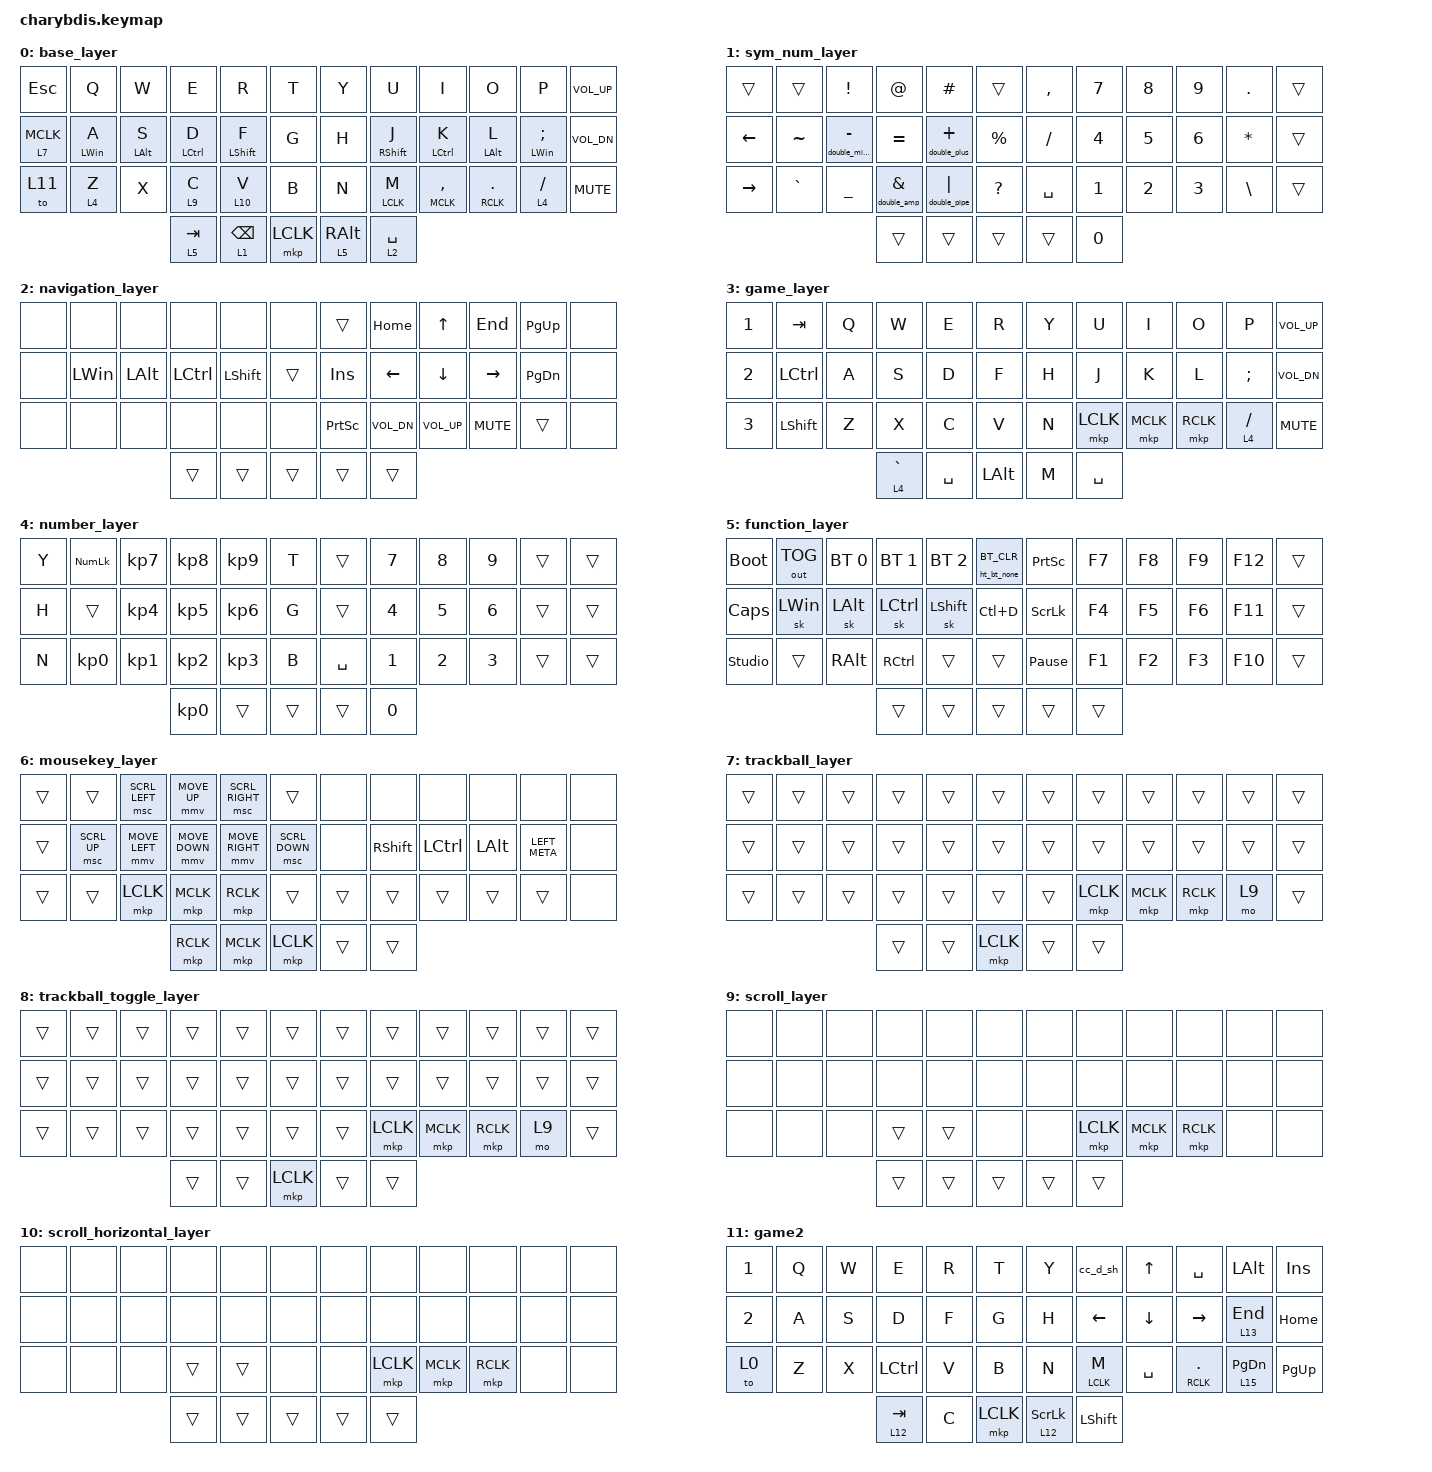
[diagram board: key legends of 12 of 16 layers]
#include <behaviors/mouse_keys.dtsi>
#include <dt-bindings/zmk/mouse.h>
#include <behaviors.dtsi>
#include <dt-bindings/zmk/bt.h>
#include <dt-bindings/zmk/keys.h>
#include <dt-bindings/zmk/outputs.h>
#include <dt-bindings/zmk/pointing.h>

//#include <dt-bindings/zmk/pointing.h>
// / {
//     chosen { zmk,matrix_transform = &default_transform; };
// };

#define LBASE 0
#define LSYM 1
#define LNAV 2
#define LGAME 3
#define LNUM 4
#define LFUNC 5
#define LMSE 6
#define LTRAC 7
#define LTOG 8
#define LSCR 9
#define LSCRH 10
#define LGAME2 11
#define LGAME_LEFT 13
#define LGAME_LEFT2 14
#define LGAME2NUM 15

&lt { quick-tap-ms = <220>; };

/ {
    trackball_auto_listener {
        compatible = "zmk,input-behavior-listener";
        device = <&vtrackball>;
        layers = <LBASE LTOG>;
        evt-type = <INPUT_EV_REL>;
        x-input-code = <INPUT_REL_X>;
        y-input-code = <INPUT_REL_Y>;
        scale-multiplier = <1>;
        scale-divisor = <3>;
        bindings = <&ib_toggle_layer LTRAC>;
    };

    trackball_listener {
        compatible = "zmk,input-behavior-listener";
        device = <&vtrackball>;
        layers = <LGAME LMSE LTRAC LGAME2 LGAME_LEFT LGAME_LEFT2>;
        evt-type = <INPUT_EV_REL>;
        x-input-code = <INPUT_REL_X>;
        y-input-code = <INPUT_REL_Y>;
        scale-multiplier = <1>;
        scale-divisor = <3>;
    };

    // input config for snipe mode

    trackball_snipe_listener {
        compatible = "zmk,input-behavior-listener";
        device = <&vtrackball>;
        layers = <LSYM>;
        evt-type = <INPUT_EV_REL>;
        x-input-code = <INPUT_REL_X>;
        y-input-code = <INPUT_REL_Y>;
        scale-multiplier = <1>;
        scale-divisor = <7>;
    };

    // input config for mouse scroll mode

    trackball_scroll_listener {
        compatible = "zmk,input-behavior-listener";
        device = <&vtrackball>;
        layers = <LSCR LNUM LGAME2NUM>;
        evt-type = <INPUT_EV_REL>;
        x-input-code = <INPUT_REL_MISC>;
        y-input-code = <INPUT_REL_WHEEL>;
        y-invert;
        bindings = <&ib_wheel_scaler 1 32>;
    };

    // input config for mouse scroll mode (horizontal)

    trackball_h_scroll_listener {
        compatible = "zmk,input-behavior-listener";
        device = <&vtrackball>;
        layers = <LSCRH>;
        evt-type = <INPUT_EV_REL>;
        x-input-code = <INPUT_REL_HWHEEL>;
        y-input-code = <INPUT_REL_MISC>;
        bindings = <&ib_h_wheel_scaler 1 32>;
    };

    // define a resolution down scaler only for INPUT_REL_WHEEL

    ib_wheel_scaler: ib_wheel_scaler {
        compatible = "zmk,input-behavior-scaler";
        #binding-cells = <2>;
        evt-type = <INPUT_EV_REL>;
        input-code = <INPUT_REL_WHEEL>;
    };

    // define a resolution down scaler only for INPUT_REL_HWHEEL (horizontal)

    ib_h_wheel_scaler: ib_h_wheel_scaler {
        compatible = "zmk,input-behavior-scaler";
        #binding-cells = <2>;
        evt-type = <INPUT_EV_REL>;
        input-code = <INPUT_REL_HWHEEL>;
    };

    // adjust cooldown waiting period for mouse key layer after activated

    ib_toggle_layer: ib_toggle_layer {
        compatible = "zmk,input-behavior-tog-layer";
        #binding-cells = <1>;
        time-to-live-ms = <800>;
    };

    behaviors {
        ht_mo_to: ht_moL_toL {
            compatible = "zmk,behavior-hold-tap";
            bindings = <&mo>, <&to>;

            #binding-cells = <2>;
            flavor = "balanced";
            tapping-term-ms = <200>;
        };

        ht_hm_rshft: hm_Rshift {
            compatible = "zmk,behavior-hold-tap";
            label = "ht_hm_rshft";
            bindings = <&kp>, <&kp>;

            #binding-cells = <2>;
            flavor = "tap-preferred";
            tapping-term-ms = <160>;
            quick-tap-ms = <220>;
        };

        ht_hm_lshft: hm_Lshift {
            compatible = "zmk,behavior-hold-tap";
            label = "ht_hm_lshft";
            bindings = <&kp>, <&kp>;

            #binding-cells = <2>;
            flavor = "tap-preferred";
            tapping-term-ms = <160>;
            quick-tap-ms = <220>;
        };

        ht_hm: homerow_mod {
            compatible = "zmk,behavior-hold-tap";
            label = "Homerow Mod";
            bindings = <&kp>, <&kp>;

            #binding-cells = <2>;
            tapping-term-ms = <220>;
            flavor = "tap-preferred";
            quick-tap-ms = <220>;
        };

        ht_gte_gt: gt_hold_gte {
            compatible = "zmk,behavior-hold-tap";
            label = "GT_GTE";
            bindings = <&gte>, <&kp>;

            #binding-cells = <2>;
            tapping-term-ms = <200>;
            flavor = "tap-preferred";
            quick-tap-ms = <200>;
        };

        ht_lte_lt: lt_hold_lte {
            compatible = "zmk,behavior-hold-tap";
            label = "LT_LTE";
            bindings = <&lte>, <&kp>;

            #binding-cells = <2>;
            tapping-term-ms = <200>;
            flavor = "tap-preferred";
            quick-tap-ms = <200>;
        };

        ht_lpar_lr: lpar_hold_lr {
            compatible = "zmk,behavior-hold-tap";
            label = "LPAR_LR";
            bindings = <&parenthesis_lr>, <&kp>;

            #binding-cells = <2>;
            tapping-term-ms = <200>;
            flavor = "tap-preferred";
            quick-tap-ms = <200>;
        };

        ht_lbrace_lr: lbrace_hold_lr {
            compatible = "zmk,behavior-hold-tap";
            label = "LBRACE_LR";
            bindings = <&braces_lr>, <&kp>;

            #binding-cells = <2>;
            tapping-term-ms = <200>;
            flavor = "tap-preferred";
            quick-tap-ms = <200>;
        };

        ht_lbracket_lr: lbracket_hold_lr {
            compatible = "zmk,behavior-hold-tap";
            label = "LBRACKET_LR";
            bindings = <&brackets_lr>, <&kp>;

            #binding-cells = <2>;
            tapping-term-ms = <200>;
            flavor = "tap-preferred";
            quick-tap-ms = <200>;
        };

        lt_mo_mkp: lt_moL_mouseKP {
            compatible = "zmk,behavior-hold-tap";
            label = "LT_MOUSEKP";
            bindings = <&mo>, <&mkp>;

            #binding-cells = <2>;
            tapping-term-ms = <200>;
        };

        ht_mkp_kp: ht_mouseKP_KP {
            compatible = "zmk,behavior-hold-tap";
            label = "HT_MOUSEKP";
            bindings = <&mkp>, <&kp>;

            #binding-cells = <2>;
            tapping-term-ms = <220>;
            quick-tap-ms = <150>;
            flavor = "tap-preferred";
        };

        mm_test: mm_test {
            compatible = "zmk,behavior-mod-morph";
            label = "MM_TEST";
            bindings = <&kp A>, <&kp B>;

            #binding-cells = <0>;
            mods = <(MOD_LSFT|MOD_RSFT)>;
            keep-mods = <(MOD_RSFT)>;
        };

        ht_pipe_double: ht_pipe_double {
            compatible = "zmk,behavior-hold-tap";
            label = "HT_PIPE_DOUBLE";
            bindings = <&double_pipe>, <&kp>;

            #binding-cells = <2>;
            tapping-term-ms = <200>;
            flavor = "tap-preferred";
            quick-tap-ms = <200>;
        };

        ht_amp_double: ht_amp_double {
            compatible = "zmk,behavior-hold-tap";
            label = "HT_AMP_DOUBLE";
            bindings = <&double_amp>, <&kp>;

            #binding-cells = <2>;
            tapping-term-ms = <200>;
            flavor = "tap-preferred";
            quick-tap-ms = <200>;
        };

        ht_bt_none: ht_bt_none {
            compatible = "zmk,behavior-hold-tap";
            label = "HT_BT_NONE";
            bindings = <&bt>, <&none>;

            #binding-cells = <2>;
            tapping-term-ms = <220>;
        };

        ht_mo_tog: ht_mo_tog {
            compatible = "zmk,behavior-hold-tap";
            label = "HT_MO_TOG";
            bindings = <&mo>, <&tog>;

            #binding-cells = <2>;
            tapping-term-ms = <200>;
        };

        ht_plus_double: ht_plus_double {
            compatible = "zmk,behavior-hold-tap";
            label = "HT_PLUS_DOUBLE";
            bindings = <&double_plus>, <&kp>;

            #binding-cells = <2>;
            tapping-term-ms = <200>;
            flavor = "tap-preferred";
            quick-tap-ms = <200>;
        };

        ht_minus_double: ht_minus_double {
            compatible = "zmk,behavior-hold-tap";
            label = "HT_MINUS_DOUBLE";
            bindings = <&double_minus>, <&kp>;

            #binding-cells = <2>;
            tapping-term-ms = <200>;
            flavor = "tap-preferred";
            quick-tap-ms = <200>;
        };

        td_f_7_8_9: td_f_7_8_9 {
            compatible = "zmk,behavior-tap-dance";
            label = "TD_F_7_8_9";
            #binding-cells = <0>;
            bindings = <&kp F>, <&kp N7>, <&kp N8>, <&kp N9>;
        };
    };

    combos {
        compatible = "zmk,combos";

        combo_lpar {
            timeout-ms = <46>;
            key-positions = <16 15>;
            bindings = <&ht_lpar_lr 0 LEFT_PARENTHESIS>;
            layers = <0 1 7 8 2>;
        };

        combo_rpar {
            timeout-ms = <45>;
            key-positions = <19 20>;
            bindings = <&kp RPAR>;
            layers = <0 7 1 8>;
        };

        combo_lbkt {
            timeout-ms = <45>;
            key-positions = <14 16>;
            bindings = <&ht_lbracket_lr 0 LEFT_BRACKET>;
            layers = <0 1 7 8>;
        };

        combo_rbkt {
            timeout-ms = <45>;
            key-positions = <19 21>;
            bindings = <&kp RBKT>;
            layers = <0 7 8 1>;
        };

        combo_lbrc {
            timeout-ms = <45>;
            key-positions = <14 15>;
            bindings = <&ht_lbrace_lr 0 LEFT_BRACE>;
            layers = <0 1 7 8>;
        };

        combo_rbrc {
            timeout-ms = <45>;
            key-positions = <20 21>;
            bindings = <&kp RIGHT_BRACE>;
            layers = <0 7 1 8>;
        };

        combo_lt {
            bindings = <&ht_lte_lt 0 LT>;
            key-positions = <14 3>;
            timeout-ms = <46>;
            layers = <0 1 7 8>;
        };

        combo_gt {
            bindings = <&ht_gte_gt 0 GT>;
            key-positions = <21 8>;
            timeout-ms = <45>;
            layers = <0 7 8 1>;
        };

        combo_copy {
            bindings = <&kp LC(C)>;
            key-positions = <27 15>;
            layers = <0 7 8>;
        };

        combo_paste {
            bindings = <&kp LC(V)>;
            key-positions = <16 28>;
            layers = <0 7 8>;
        };

        combo_num0 {
            bindings = <&kp N0>;
            key-positions = <31 19>;
            layers = <0 1 4 7 8>;
        };

        combo_num1 {
            bindings = <&kp NUMBER_1>;
            key-positions = <32 20>;
            layers = <0 1 4 7 8>;
        };

        combo_altF4 {
            bindings = <&kp LA(F4)>;
            key-positions = <1 4>;
            layers = <0 7 8>;
        };

        combo_escL {
            bindings = <&kp ESCAPE>;
            key-positions = <28 27>;
            layers = <0 1 2 6 7 8 13 14>;
        };

        combo_delL {
            bindings = <&kp DEL>;
            key-positions = <26 28>;
            layers = <0 1 7 8 2 4>;
        };

        combo_enterL {
            bindings = <&kp ENTER>;
            key-positions = <27 26>;
            layers = <0 7 1 8 13 14>;
        };

        combo_sqtL {
            bindings = <&kp SQT>;
            key-positions = <3 16>;
            layers = <0 1 7 8 2>;
        };

        combo_toggle_Trackball {
            bindings = <&tog 8>;
            key-positions = <31 34>;
            layers = <0 7 8>;
        };

        combo_toggle_game {
            bindings = <&tog 11>;
            key-positions = <24 35>;
            layers = <0 3 11>;
        };

        combo_space {
            bindings = <&kp SPACE>;
            key-positions = <16 4>;
            layers = <0 7 1 8 11 13 14>;
        };

        combo_caps {
            bindings = <&caps_word>;
            key-positions = <2 14>;
            layers = <0 7 1 8>;
        };

        combo_bspc {
            bindings = <&kp BACKSPACE>;
            key-positions = <7 19>;
            layers = <0 1 6 8 11 13 14>;
        };

        combo_tab {
            bindings = <&kp TAB>;
            key-positions = <8 20>;
            layers = <0 1 7 8>;
        };

        combo_forward {
            bindings = <&kp LA(RIGHT)>;
            key-positions = <30 31>;
            layers = <0 7 8 6>;
        };

        combo_back {
            bindings = <&kp LA(LEFT_ARROW)>;
            key-positions = <18 19>;
            layers = <0 7 8 6>;
        };

        combo_kor_T {
            bindings = <&kp LG(GRAVE)>;
            key-positions = <3 4>;
            timeout-ms = <50>;
            layers = <0 7 8>;
        };

        combo_kor_R {
            bindings = <&kp LC(LG(GRAVE))>;
            key-positions = <3 2>;
            timeout-ms = <50>;
            layers = <0 7 8>;
        };

        combo_escR {
            bindings = <&kp ESCAPE>;
            key-positions = <32 31>;
            layers = <0 1 7 8 2 3 11 13 14>;
        };

        combo_delR {
            bindings = <&kp DELETE>;
            key-positions = <31 33>;
            layers = <0 1 6 8 3 11 13 14>;
        };

        combo_enterR {
            bindings = <&kp ENTER>;
            key-positions = <33 32>;
            layers = <0 1 7 8 3 11 13 14>;
        };

        combo_sqtR {
            bindings = <&kp DQT>;
            key-positions = <8 19>;
            layers = <0 1 7 8>;
        };

        combo_caret {
            bindings = <&kp CARET>;
            key-positions = <15 28>;
            layers = <0 1 7 8>;
        };

        combo_dollar {
            bindings = <&kp DOLLAR>;
            key-positions = <31 20>;
            layers = <0 1 7 8>;
        };

        combo_scroll {
            bindings = <&tog 9>;
            key-positions = <40 39>;
            layers = <0 6 8 9>;
        };

        game_left_3 {
            bindings = <&kp NUMBER_3>;
            key-positions = <2 3>;
            layers = <13 14>;
        };

        game_left_4 {
            bindings = <&kp NUMBER_4>;
            key-positions = <3 4>;
            layers = <13 14>;
        };

        toggle_game_left {
            bindings = <&tog 13>;
            key-positions = <28 29>;
            layers = <11 13>;
        };

        game_shift {
            bindings = <&kp LEFT_SHIFT>;
            key-positions = <26 25>;
            layers = <13 14>;
        };

        toggle_14 {
            bindings = <&tog 14>;
            key-positions = <28 16>;
            layers = <11 14>;
        };

        toggle_game_left_r {
            bindings = <&tog 13>;
            key-positions = <30 31>;
            layers = <11 13>;
        };

        toggle_game_left2_r {
            bindings = <&tog 14>;
            key-positions = <19 31>;
            layers = <11 14>;
        };
    };

    macros {
        gte: gte {
            compatible = "zmk,behavior-macro";
            #binding-cells = <0>;
            bindings = <&macro_tap_time 5>, <&kp GT &kp EQUAL>;

            label = "GTE";
        };

        lte: lte {
            compatible = "zmk,behavior-macro";
            #binding-cells = <0>;
            bindings = <&macro_tap_time 5>, <&kp LT &kp EQUAL>;

            label = "LTE";
        };

        parenthesis_lr: parenthesis_lr {
            compatible = "zmk,behavior-macro";
            #binding-cells = <0>;
            bindings = <&macro_tap_time 5>, <&kp LPAR &kp RPAR>;

            label = "PARENTHESIS_LR";
        };

        braces_lr: braces_lr {
            compatible = "zmk,behavior-macro";
            #binding-cells = <0>;
            bindings = <&macro_tap_time 5>, <&kp LBRC &kp RBRC>;

            label = "BRACES_LR";
        };

        brackets_lr: brackets_lr {
            compatible = "zmk,behavior-macro";
            #binding-cells = <0>;
            bindings = <&macro_tap_time 5>, <&kp LBKT &kp RBKT>;

            label = "BRACKETS_LR";
        };

        double_pipe: double_pipe {
            compatible = "zmk,behavior-macro";
            #binding-cells = <0>;
            bindings = <&macro_tap_time 5>, <&kp PIPE &kp PIPE>;

            label = "DOUBLE_PIPE";
        };

        double_amp: double_amp {
            compatible = "zmk,behavior-macro";
            #binding-cells = <0>;
            bindings = <&macro_tap_time 5>, <&kp AMPS &kp AMPS>;

            label = "DOUBLE_AMP";
        };

        double_plus: hold_plus {
            compatible = "zmk,behavior-macro";
            #binding-cells = <0>;
            bindings = <&macro_tap_time 5>, <&kp PLUS &kp PLUS>;

            label = "HOLD_PLUS";
        };

        double_minus: double_minus {
            compatible = "zmk,behavior-macro";
            #binding-cells = <0>;
            bindings = <&macro_tap_time 5>, <&kp MINUS &kp MINUS>;

            label = "DOUBLE_MINUS";
        };

        d_sh: crumeso {
            compatible = "zmk,behavior-macro";
            #binding-cells = <0>;
            bindings =
                <&kp D>,
                <&macro_wait_time 200>,
                <&kp LEFT_SHIFT>,
                <&macro_wait_time 210>;

            label = "CRUMESO";
        };

        cc_d_sh: left_alt {
            compatible = "zmk,behavior-macro";
            #binding-cells = <0>;
            bindings =
                <&kp C>,
                <&macro_wait_time 200>,
                <&kp C>,
                <&macro_wait_time 300>,
                <&kp D &kp LEFT_SHIFT>;

            label = "LEFT_ALT";
        };

        s_sh: s_sh {
            compatible = "zmk,behavior-macro";
            #binding-cells = <0>;
            bindings =
                <&kp S>,
                <&macro_wait_time 300>,
                <&kp LEFT_SHIFT>,
                <&macro_wait_time 300>;

            label = "S_SH";
        };

        sp: sp {
            compatible = "zmk,behavior-macro";
            #binding-cells = <0>;
            bindings = <&kp SPACE &kp SPACE &kp SPACE &kp SPACE &kp SPACE &kp SPACE &kp SPACE &kp SPACE>;
            label = "SP";
        };
    };

    keymap {
        compatible = "zmk,keymap";

        base_layer {
            bindings = <
&kp ESC            &kp Q              &kp W              &kp E                  &kp R                      &kp T        &kp Y            &kp U                       &kp I                  &kp O                &kp P                      &kp C_VOL_UP
&lt_mo_mkp 7 MCLK  &ht_hm LEFT_WIN A  &ht_hm LEFT_ALT S  &ht_hm LEFT_CONTROL D  &ht_hm_lshft LEFT_SHIFT F  &kp G        &kp H            &ht_hm_rshft RIGHT_SHIFT J  &ht_hm LEFT_CONTROL K  &ht_hm LEFT_ALT L    &ht_hm LEFT_WIN SEMICOLON  &kp C_VOL_DN
&to 11             &lt 4 Z            &kp X              &lt 9 C                &lt 10 V                   &kp B        &kp N            &ht_mkp_kp LCLK M           &ht_mkp_kp MCLK COMMA  &ht_mkp_kp RCLK DOT  &lt 4 SLASH                &kp C_MUTE
                                                         &lt 5 TAB              &lt 1 BACKSPACE            &mkp LCLK    &lt 5 RIGHT_ALT  &lt 2 SPACE
            >;
        };

        sym_num_layer {
            bindings = <
&trans          &trans     &kp EXCLAMATION           &kp AT                 &kp HASH                &trans          &kp COMMA  &kp N7        &kp N8  &kp N9        &kp DOT        &trans
&kp LEFT_ARROW  &kp TILDE  &ht_minus_double 0 MINUS  &kp EQUAL              &ht_plus_double 0 PLUS  &kp PERCENT     &kp SLASH  &kp N4        &kp N5  &kp N6        &kp STAR       &trans
&kp RIGHT       &kp GRAVE  &kp UNDER                 &ht_amp_double 0 AMPS  &ht_pipe_double 0 PIPE  &kp QUESTION    &kp SPACE  &kp NUMBER_1  &kp N2  &kp NUMBER_3  &kp BACKSLASH  &trans
                                                     &trans                 &trans                  &trans          &trans     &kp N0
            >;
        };

        navigation_layer {
            bindings = <
&none  &none     &none     &none             &none           &none     &trans           &kp HOME        &kp UP_ARROW  &kp END     &kp PG_UP      &none
&none  &kp LWIN  &kp LALT  &kp LEFT_CONTROL  &kp LEFT_SHIFT  &trans    &kp INS          &kp LEFT_ARROW  &kp DOWN      &kp RIGHT   &kp PAGE_DOWN  &none
&none  &none     &none     &none             &none           &none     &kp PRINTSCREEN  &kp C_VOL_DN    &kp C_VOL_UP  &kp C_MUTE  &trans         &none
                           &trans            &trans          &trans    &trans           &trans
            >;
        };

        game_layer {
            bindings = <
&kp N1  &kp TAB    &kp Q  &kp W        &kp E      &kp R           &kp Y  &kp U      &kp I      &kp O      &kp P        &kp C_VOL_UP
&kp N2  &kp LCTRL  &kp A  &kp S        &kp D      &kp F           &kp H  &kp J      &kp K      &kp L      &kp SEMI     &kp C_VOL_DN
&kp N3  &kp LSHFT  &kp Z  &kp X        &kp C      &kp V           &kp N  &mkp LCLK  &mkp MCLK  &mkp RCLK  &lt 4 SLASH  &kp C_MUTE
                          &lt 4 GRAVE  &kp SPACE  &kp LEFT_ALT    &kp M  &kp SPACE
            >;
        };

        number_layer {
            bindings = <
&kp Y  &kp KP_NUMLOCK  &kp KP_NUMBER_7  &kp KP_NUMBER_8  &kp KP_NUMBER_9  &kp T     &trans     &kp N7  &kp N8  &kp N9  &trans  &trans
&kp H  &trans          &kp KP_NUMBER_4  &kp KP_NUMBER_5  &kp KP_NUMBER_6  &kp G     &trans     &kp N4  &kp N5  &kp N6  &trans  &trans
&kp N  &kp KP_N0       &kp KP_N1        &kp KP_NUMBER_2  &kp KP_NUMBER_3  &kp B     &kp SPACE  &kp N1  &kp N2  &kp N3  &trans  &trans
                                        &kp KP_NUMBER_0  &trans           &trans    &trans     &kp N0
            >;
        };

        function_layer {
            bindings = <
&bootloader     &out OUT_TOG  &bt BT_SEL 0  &bt BT_SEL 1  &bt BT_SEL 2  &ht_bt_none BT_CLR    &kp PRINTSCREEN  &kp F7  &kp F8  &kp F9  &kp F12  &trans
&kp CAPSLOCK    &sk LWIN      &sk LEFT_ALT  &sk LCTRL     &sk LSHIFT    &kp LC(D)             &kp SCROLLLOCK   &kp F4  &kp F5  &kp F6  &kp F11  &trans
&studio_unlock  &trans        &kp RALT      &kp RCTRL     &trans        &trans                &kp PAUSE_BREAK  &kp F1  &kp F2  &kp F3  &kp F10  &trans
                                            &trans        &trans        &trans                &trans           &trans
            >;
        };

        mousekey_layer {
            bindings = <
&trans  &trans        &msc SCRL_LEFT  &mmv MOVE_UP    &msc SCRL_RIGHT  &trans            &none   &none            &none      &none         &none          &none
&trans  &msc SCRL_UP  &mmv MOVE_LEFT  &mmv MOVE_DOWN  &mmv MOVE_RIGHT  &msc SCRL_DOWN    &none   &kp RIGHT_SHIFT  &kp LCTRL  &kp LEFT_ALT  &kp LEFT_META  &none
&trans  &trans        &mkp LCLK       &mkp MCLK       &mkp RCLK        &trans            &trans  &trans           &trans     &trans        &trans         &none
                                      &mkp RCLK       &mkp MCLK        &mkp LCLK         &trans  &trans
            >;
        };

        trackball_layer {
            bindings = <
&trans  &trans  &trans  &trans  &trans  &trans       &trans  &trans     &trans     &trans     &trans  &trans
&trans  &trans  &trans  &trans  &trans  &trans       &trans  &trans     &trans     &trans     &trans  &trans
&trans  &trans  &trans  &trans  &trans  &trans       &trans  &mkp LCLK  &mkp MCLK  &mkp RCLK  &mo 9   &trans
                        &trans  &trans  &mkp LCLK    &trans  &trans
            >;
        };

        trackball_toggle_layer {
            bindings = <
&trans  &trans  &trans  &trans  &trans  &trans       &trans  &trans     &trans     &trans     &trans  &trans
&trans  &trans  &trans  &trans  &trans  &trans       &trans  &trans     &trans     &trans     &trans  &trans
&trans  &trans  &trans  &trans  &trans  &trans       &trans  &mkp LCLK  &mkp MCLK  &mkp RCLK  &mo 9   &trans
                        &trans  &trans  &mkp LCLK    &trans  &trans
            >;
        };

        scroll_layer {
            bindings = <
&none  &none  &none  &none   &none   &none     &none   &none      &none      &none      &none  &none
&none  &none  &none  &none   &none   &none     &none   &none      &none      &none      &none  &none
&none  &none  &none  &trans  &trans  &none     &none   &mkp LCLK  &mkp MCLK  &mkp RCLK  &none  &none
                     &trans  &trans  &trans    &trans  &trans
            >;
        };

        scroll_horizontal_layer {
            bindings = <
&none  &none  &none  &none   &none   &none     &none   &none      &none      &none      &none  &none
&none  &none  &none  &none   &none   &none     &none   &none      &none      &none      &none  &none
&none  &none  &none  &trans  &trans  &none     &none   &mkp LCLK  &mkp MCLK  &mkp RCLK  &none  &none
                     &trans  &trans  &trans    &trans  &trans
            >;
        };

        game2 {
            bindings = <
&kp N1  &kp Q  &kp W  &kp E       &kp R  &kp T        &kp Y              &cc_d_sh           &kp UP_ARROW    &kp SPACE               &kp LEFT_ALT      &kp INSERT
&kp N2  &kp A  &kp S  &kp D       &kp F  &kp G        &kp H              &kp LEFT_ARROW     &kp DOWN_ARROW  &kp RIGHT_ARROW         &lt 13 END        &kp HOME
&to 0   &kp Z  &kp X  &kp LCTRL   &kp V  &kp B        &kp N              &ht_mkp_kp LCLK M  &kp SPACE       &ht_mkp_kp RCLK PERIOD  &lt 15 PAGE_DOWN  &kp PAGE_UP
                      &lt 12 TAB  &kp C  &mkp LCLK    &lt 12 SCROLLLOCK  &kp LEFT_SHIFT
            >;
        };

        game2_ {
            bindings = <
&kp GRAVE  &kp NUMBER_6  &kp N7  &kp NUMBER_8  &kp N9  &kp NUMBER_0    &kp MINUS  &kp U   &kp I             &kp O              &kp LALT  &kp C_VOLUME_UP
&kp PLUS   &kp F1        &kp F2  &kp F3        &kp F4  &kp F5          &kp F11    &kp J   &kp K             &kp L              &kp SEMI  &kp C_VOL_DN
&trans     &kp F6        &kp F7  &kp F8        &kp F9  &kp F10         &kp F12    &kp P   &kp LEFT_BRACKET  &kp RIGHT_BRACKET  &kp SQT   &kp C_MUTE
                                 &trans        &trans  &trans          &trans     &trans
            >;
        };

        Left {
            bindings = <
&td_f_7_8_9    &kp Q  &kp LA(J)       &kp UP_ARROW    &kp LA(L)  &kp DELETE    &kp Q                 &kp DELETE      &kp UP_ARROW    &kp HOME         &kp V     &kp C_VOLUME_UP
&kp END        &kp A  &kp LEFT_ARROW  &kp DOWN_ARROW  &kp RIGHT  &kp A         &kp A                 &kp LEFT_ARROW  &kp DOWN_ARROW  &kp RIGHT_ARROW  &kp END   &kp C_VOL_DN
&kp LA(COMMA)  &kp V  &kp F           &kp W           &kp R      &kp HOME      &kp H                 &mkp LCLK       &d_sh           &mkp RCLK        &lt 15 F  &kp C_MUTE
                                      &d_sh           &kp C      &mkp LCLK     &kp LA(C_PLAY_PAUSE)  &kp C
            >;
        };

        Left2T {
            bindings = <
&td_f_7_8_9    &kp Q           &kp LA(J)       &kp UP_ARROW    &kp LA(L)  &kp DELETE    &kp Q                 &kp DELETE      &kp UP_ARROW    &kp HOME         &kp C     &kp C_VOLUME_UP
&kp END        &kp A           &kp LEFT_ARROW  &kp DOWN_ARROW  &kp RIGHT  &kp A         &kp A                 &kp LEFT_ARROW  &kp DOWN_ARROW  &kp RIGHT_ARROW  &kp END   &kp C_VOL_DN
&kp LA(COMMA)  &kp LEFT_SHIFT  &kp END         &kp D           &kp V      &kp HOME      &kp H                 &mkp LCLK       &kp D           &mkp RCLK        &lt 15 F  &kp C_MUTE
                                               &d_sh           &kp C      &mkp LCLK     &kp LA(C_PLAY_PAUSE)  &kp LEFT_SHIFT
            >;
        };

        game2_num {
            bindings = <
&trans  &trans  &trans     &kp LA(I)      &trans     &kp LA(F9)       &kp LA(J)  &kp N7  &kp N8  &kp N9  &sp     &trans
&trans  &trans  &kp LA(J)  &kp LA(K)      &kp LA(L)  &kp LA(TAB)      &kp LA(L)  &kp N4  &kp N5  &kp N6  &trans  &trans
&trans  &trans  &trans     &kp LA(COMMA)  &trans     &kp LA(ENTER)    &kp SPACE  &kp N1  &kp N2  &kp N3  &trans  &trans
                           &mkp RCLK      &mkp MCLK  &mkp LCLK        &trans     &kp N0
            >;
        };
    };
};
